VERSION ""

NS_ :

BS_:

BU_:

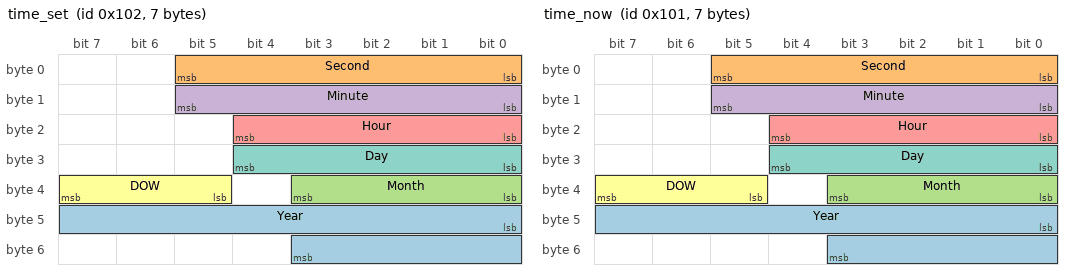
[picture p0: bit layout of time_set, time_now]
BO_ 258 time_set: 7 Vector__XXX
 SG_ Year : 40|12@1+ (1,0) [0|4095] "" Vector__XXX
 SG_ Second : 0|6@1+ (1,0) [0|63] "" Vector__XXX
 SG_ Month : 32|4@1+ (1,0) [0|15] "" Vector__XXX
 SG_ Minute : 8|6@1+ (1,0) [0|63] "" Vector__XXX
 SG_ Hour : 16|5@1+ (1,0) [0|31] "" Vector__XXX
 SG_ DOW : 37|3@1+ (1,0) [0|7] "" Vector__XXX
 SG_ Day : 24|5@1+ (1,0) [0|31] "" Vector__XXX

BO_ 257 time_now: 7 Vector__XXX
 SG_ Year : 40|12@1+ (1,0) [0|4095] "" Vector__XXX
 SG_ Second : 0|6@1+ (1,0) [0|63] "" Vector__XXX
 SG_ Month : 32|4@1+ (1,0) [0|15] "" Vector__XXX
 SG_ Minute : 8|6@1+ (1,0) [0|63] "" Vector__XXX
 SG_ Hour : 16|5@1+ (1,0) [0|31] "" Vector__XXX
 SG_ DOW : 37|3@1+ (1,0) [0|7] "" Vector__XXX
 SG_ Day : 24|5@1+ (1,0) [0|31] "" Vector__XXX

BO_ 256 New_Message: 1 Vector__XXX
 SG_ Signal_1 : 0|8@1+ (1,0) [0|255] "" Vector__XXX

BA_DEF_  "BusType" STRING ;
BA_DEF_DEF_  "BusType" "CAN";
